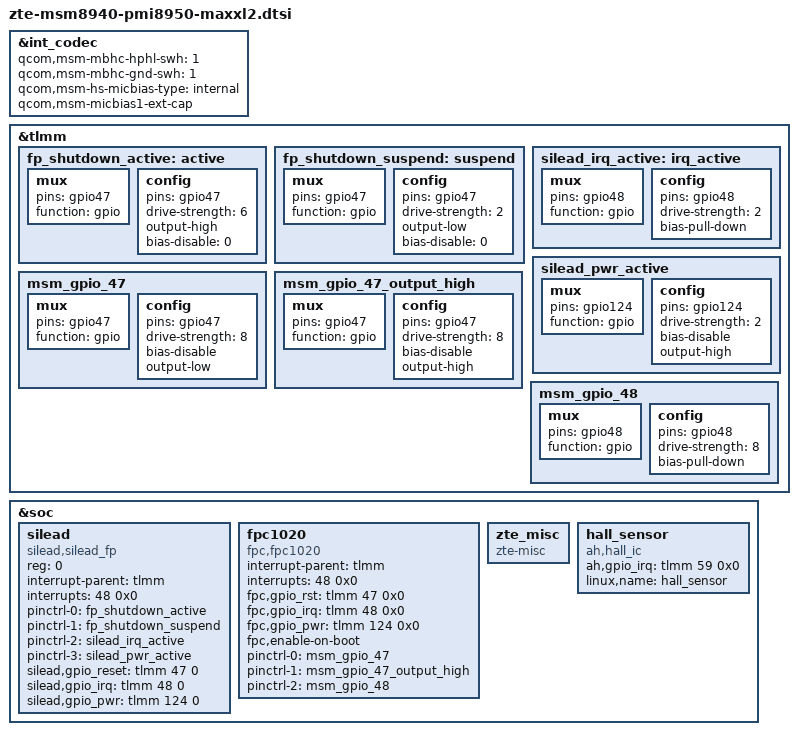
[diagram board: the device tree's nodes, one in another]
/*
 * Copyright (c) 2016, The Linux Foundation. All rights reserved.
 *
 * This program is free software; you can redistribute it and/or modify
 * it under the terms of the GNU General Public License version 2 and
 * only version 2 as published by the Free Software Foundation.
 *
 * This program is distributed in the hope that it will be useful,
 * but WITHOUT ANY WARRANTY; without even the implied warranty of
 * MERCHANTABILITY or FITNESS FOR A PARTICULAR PURPOSE.  See the
 * GNU General Public License for more details.
 */

&int_codec {
	qcom,msm-mbhc-hphl-swh = <1>;
	qcom,msm-mbhc-gnd-swh = <1>;
	qcom,msm-hs-micbias-type = "internal";
	qcom,msm-micbias1-ext-cap;
};


&tlmm {
	fp_shutdown_active:active{
		mux{
			pins = "gpio47";
			function = "gpio";
		};
		config{
			pins = "gpio47";
			drive-strength = <6>;
			output-high;
			bias-disable = <0>;
		};
	};

	fp_shutdown_suspend:suspend{
		mux{
			pins = "gpio47";
			function = "gpio";
		};
		config{
			pins = "gpio47";
			drive-strength = <2>;
			output-low;
			bias-disable = <0>;
		};
	};

	silead_irq_active:irq_active{
		mux{
			pins = "gpio48";
			function = "gpio";
		};
		config{
			pins = "gpio48";
			drive-strength = <2>;
			bias-pull-down;
		};
	};

	silead_pwr_active: silead_pwr_active {
		mux{
			pins = "gpio124";
			function = "gpio";
		};
		config {
			pins = "gpio124";
			drive-strength = <2>;
			bias-disable;
			output-high;
		};
	};

    msm_gpio_47: msm_gpio_47{
		mux {
			pins = "gpio47";
			function = "gpio";
		};
		config {
			pins = "gpio47";
			drive-strength = <8>;
			bias-disable;
			output-low;
		};
	};
	msm_gpio_47_output_high: msm_gpio_47_output_high {
		mux {
			pins = "gpio47";
			function = "gpio";
		};
		config {
			pins = "gpio47";
			drive-strength = <8>;
			bias-disable;
			output-high;
		};
	};
	msm_gpio_48: msm_gpio_48 {
		mux {
			pins = "gpio48";
			function = "gpio";
		};
		config {
			pins = "gpio48";
			drive-strength = <8>;
			bias-pull-down;
		};
	};
};
/*fingerprint pinctrl end*/

&soc {
		silead {
			status = "ok";
			reg = <0>;
			compatible = "silead,silead_fp";
			interrupt-parent = <&tlmm>;
			interrupts = <48 0x0>;

			pinctrl-names = "silead_active", "silead_suspend", "silead_irq", "pwr_active";
			pinctrl-0 = <&fp_shutdown_active>;
			pinctrl-1 = <&fp_shutdown_suspend>;
			pinctrl-2 = <&silead_irq_active>;
			pinctrl-3 = <&silead_pwr_active>;

			silead,gpio_reset = <&tlmm 47 0>;
			silead,gpio_irq = <&tlmm 48 0>;
			silead,gpio_pwr = <&tlmm 124 0>;
			interrupt-names = "sl_wake_up";
		};
		fpc1020 {
			status = "ok";
			compatible = "fpc,fpc1020";
			interrupt-parent = <&tlmm>;
			interrupts = <48 0x0>;
			fpc,gpio_rst  = <&tlmm 47 0x0>;
			fpc,gpio_irq  = <&tlmm 48 0x0>;
			fpc,gpio_pwr  = <&tlmm 124 0x0>;
			fpc,enable-on-boot;
			/* fpc,enable-wakeup; */

			pinctrl-names = "fpc1020_reset_reset", "fpc1020_reset_active", "fpc1020_irq_active";

			pinctrl-0 = <&msm_gpio_47>;
			pinctrl-1 = <&msm_gpio_47_output_high>;
			pinctrl-2 = <&msm_gpio_48>;
	};
	zte_misc {
		compatible = "zte-misc";
	};
	hall_sensor {
		compatible = "ah,hall_ic";
		ah,gpio_irq = <&tlmm 59 0x0>;
		linux,name = "hall_sensor";
	};
};


